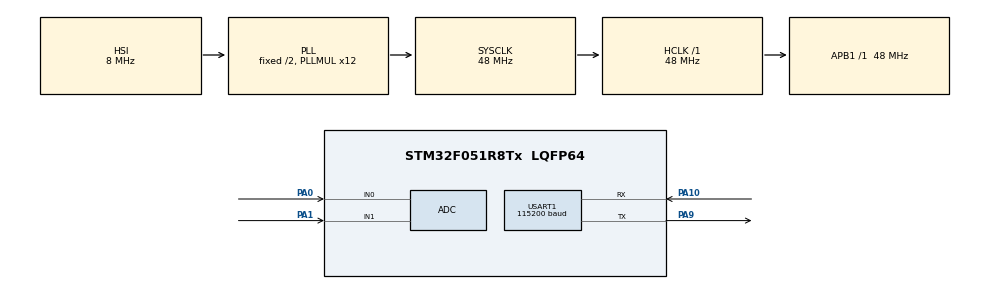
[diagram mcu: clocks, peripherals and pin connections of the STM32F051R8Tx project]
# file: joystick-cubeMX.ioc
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ADC.AWD1HighThreshold=2873
ADC.AWD1LowThreshold=1226
ADC.ClockPrescaler=ADC_CLOCK_ASYNC_DIV1
ADC.ContinuousConvMode=ENABLE
ADC.DMAContinuousRequests=DISABLE
ADC.EnableAnalogWatchDog=true
ADC.ExternalTrigConv=ADC_SOFTWARE_START
ADC.Overrun=ADC_OVR_DATA_OVERWRITTEN
ADC.SamplingTime=ADC_SAMPLETIME_239CYCLES_5
ADC.WatchdogMode=ADC_ANALOGWATCHDOG_ALL_REG
Mcu.Family=STM32F0
Mcu.Name=STM32F051R8Tx
Mcu.Package=LQFP64
NVIC.TIM1_BRK_UP_TRG_COM_IRQn=true\:0\:0\:false\:false\:true\:true\:true\:true
PA0.Mode=IN0
PA0.Signal=ADC_IN0
PA1.Mode=IN1
PA1.Signal=ADC_IN1
PA10.Mode=Asynchronous
PA10.Signal=USART1_RX
PA13.Mode=Serial_Wire
PA13.Signal=SYS_SWDIO
PA14.Mode=Serial_Wire
PA14.Signal=SYS_SWCLK
PA9.Mode=Asynchronous
PA9.Signal=USART1_TX
ProjectManager.HeapSize=0x200
ProjectManager.StackSize=0x400
ProjectManager.TargetToolchain=Makefile
RCC.AHBFreq_Value=48000000
RCC.APB1Freq_Value=48000000
RCC.APB1TimFreq_Value=48000000
RCC.HCLKFreq_Value=48000000
RCC.PLLMUL=RCC_PLL_MUL12
RCC.SYSCLKFreq_VALUE=48000000
RCC.SYSCLKSource=RCC_SYSCLKSOURCE_PLLCLK
TIM1.Period=0xffff
TIM1.TIM_MasterSlaveMode=TIM_MASTERSLAVEMODE_DISABLE
USART1.BaudRate=115200
USART1.Mode=MODE_TX
USART1.VirtualMode-Asynchronous=VM_ASYNC
VP_TIM1_VS_ClockSourceINT.Mode=Internal
board=STM32F0DISCOVERY

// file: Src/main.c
/* USER CODE BEGIN Header */
/**
 ******************************************************************************
 * @file           : main.c
 * @brief          : Main program body
 ******************************************************************************
 * @attention
 *
 * Copyright (c) 2024 STMicroelectronics.
 * All rights reserved.
 *
 * This software is licensed under terms that can be found in the LICENSE file
 * in the root directory of this software component.
 * If no LICENSE file comes with this software, it is provided AS-IS.
 *
 ******************************************************************************
 */
/* USER CODE END Header */
#include "main.h"
#include "adc.h"
#include "gpio.h"
#include "tim.h"
#include "usart.h"

void SystemClock_Config(void);

int main(void) {

  /* MCU Configuration--------------------------------------------------------*/

  /* Reset of all peripherals, Initializes the Flash interface and the Systick.
   */
  HAL_Init();

  /* Configure the system clock */
  SystemClock_Config();

  /* Initialize all configured peripherals */
  MX_GPIO_Init();
  MX_ADC_Init();
  MX_USART1_UART_Init();
  MX_TIM1_Init();
  /* USER CODE BEGIN 2 */
  HAL_TIM_Base_Start_IT(&htim1);
  // HAL_ADCEx_Calibration_Start(&hadc);
  // HAL_ADC_Start_DMA(&hadc, (uint32_t*)value, sizeof(value[0]));
  uint16_t x_value;
  uint16_t y_value;
  /* USER CODE END 2 */

  /* Infinite loop */
  /* USER CODE BEGIN WHILE */

  while (1) {

    x_value = read_adc_channel_0();
    y_value = read_adc_channel_1();

	//printf("[%ld] x: %d y: %d\r\n", get_time_ms(), x_value, y_value);
	printf("%d,%d,%d\r\n", get_time_ms(), x_value, y_value);

    delay_ms(10);

    /* USER CODE END WHILE */

  }
}

void SystemClock_Config(void) {
  RCC_OscInitTypeDef RCC_OscInitStruct = {0};
  RCC_ClkInitTypeDef RCC_ClkInitStruct = {0};
  RCC_PeriphCLKInitTypeDef PeriphClkInit = {0};

  /** Initializes the RCC Oscillators according to the specified parameters
   * in the RCC_OscInitTypeDef structure.
   */
  RCC_OscInitStruct.OscillatorType =
      RCC_OSCILLATORTYPE_HSI | RCC_OSCILLATORTYPE_HSI14;
  RCC_OscInitStruct.HSIState = RCC_HSI_ON;
  RCC_OscInitStruct.HSI14State = RCC_HSI14_ON;
  RCC_OscInitStruct.HSICalibrationValue = RCC_HSICALIBRATION_DEFAULT;
  RCC_OscInitStruct.HSI14CalibrationValue = 16;
  RCC_OscInitStruct.PLL.PLLState = RCC_PLL_ON;
  RCC_OscInitStruct.PLL.PLLSource = RCC_PLLSOURCE_HSI;
  RCC_OscInitStruct.PLL.PLLMUL = RCC_PLL_MUL12;
  RCC_OscInitStruct.PLL.PREDIV = RCC_PREDIV_DIV1;
  if (HAL_RCC_OscConfig(&RCC_OscInitStruct) != HAL_OK) {
    Error_Handler();
  }

  /** Initializes the CPU, AHB and APB buses clocks
   */
  RCC_ClkInitStruct.ClockType =
      RCC_CLOCKTYPE_HCLK | RCC_CLOCKTYPE_SYSCLK | RCC_CLOCKTYPE_PCLK1;
  RCC_ClkInitStruct.SYSCLKSource = RCC_SYSCLKSOURCE_PLLCLK;
  RCC_ClkInitStruct.AHBCLKDivider = RCC_SYSCLK_DIV1;
  RCC_ClkInitStruct.APB1CLKDivider = RCC_HCLK_DIV1;

  if (HAL_RCC_ClockConfig(&RCC_ClkInitStruct, FLASH_LATENCY_1) != HAL_OK) {
    Error_Handler();
  }
  PeriphClkInit.PeriphClockSelection = RCC_PERIPHCLK_USART1;
  PeriphClkInit.Usart1ClockSelection = RCC_USART1CLKSOURCE_PCLK1;
  if (HAL_RCCEx_PeriphCLKConfig(&PeriphClkInit) != HAL_OK) {
    Error_Handler();
  }
}

void Error_Handler(void) {
  __disable_irq();
  while (1) {
  }
}
